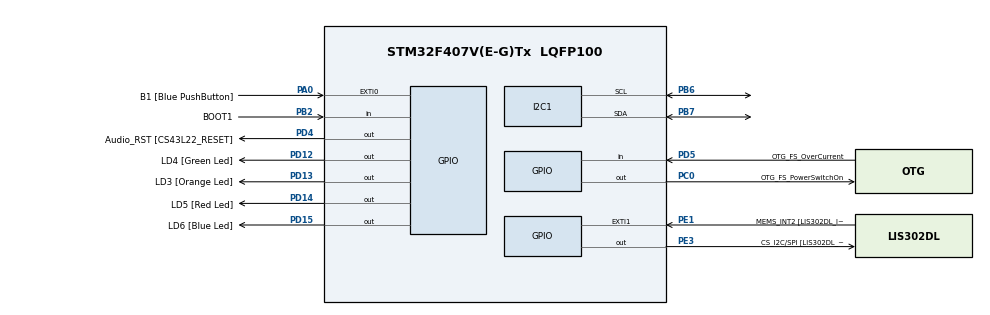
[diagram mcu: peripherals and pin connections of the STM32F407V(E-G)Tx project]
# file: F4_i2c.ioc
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Mcu.Family=STM32F4
Mcu.Name=STM32F407V(E-G)Tx
Mcu.Package=LQFP100
NVIC.PriorityGroup=NVIC_PRIORITYGROUP_0
PA0-WKUP.GPIO_Label=B1 [Blue PushButton]
PA0-WKUP.GPIO_ModeDefaultEXTI=GPIO_MODE_EVT_RISING
PA0-WKUP.GPIO_PuPd=GPIO_NOPULL
PA0-WKUP.Signal=GPXTI0
PA10.GPIO_Label=OTG_FS_ID
PA10.GPIO_Mode=GPIO_MODE_AF_PP
PA10.GPIO_PuPd=GPIO_NOPULL
PA10.GPIO_Speed=GPIO_SPEED_LOW
PA10.Signal=USB_OTG_FS_ID
PA11.GPIO_Label=OTG_FS_DM
PA11.GPIO_Mode=GPIO_MODE_AF_PP
PA11.GPIO_PuPd=GPIO_NOPULL
PA11.GPIO_Speed=GPIO_SPEED_LOW
PA11.Signal=USB_OTG_FS_DM
PA12.GPIO_Label=OTG_FS_DP
PA12.GPIO_Mode=GPIO_MODE_AF_PP
PA12.GPIO_PuPd=GPIO_NOPULL
PA12.GPIO_Speed=GPIO_SPEED_LOW
PA12.Signal=USB_OTG_FS_DP
PA13.GPIO_Label=SWDIO
PA13.Mode=Trace-Asynchronous_SW
PA13.Signal=SYS_JTMS-SWDIO
PA14.GPIO_Label=SWCLK
PA14.Mode=Trace-Asynchronous_SW
PA14.Signal=SYS_JTCK-SWCLK
PA4.GPIO_Label=I2S3_WS [CS43L22_LRCK]
PA4.GPIO_Mode=GPIO_MODE_AF_PP
PA4.GPIO_PuPd=GPIO_NOPULL
PA4.GPIO_Speed=GPIO_SPEED_LOW
PA4.Signal=I2S3_WS
PA5.GPIO_Label=SPI1_SCK [LIS302DL_SCL/SPC]
PA5.GPIO_Mode=GPIO_MODE_AF_PP
PA5.GPIO_PuPd=GPIO_NOPULL
PA5.GPIO_Speed=GPIO_SPEED_LOW
PA5.Signal=SPI1_SCK
PA6.GPIO_Label=SPI1_MISO [LIS302DL_SDO]
PA6.GPIO_Mode=GPIO_MODE_AF_PP
PA6.GPIO_PuPd=GPIO_NOPULL
PA6.GPIO_Speed=GPIO_SPEED_LOW
PA6.Signal=SPI1_MISO
PA7.GPIO_Label=SPI1_MOSI [LIS302DL_SDA/SDI/SDO]
PA7.GPIO_Mode=GPIO_MODE_AF_PP
PA7.GPIO_PuPd=GPIO_NOPULL
PA7.GPIO_Speed=GPIO_SPEED_LOW
PA7.Signal=SPI1_MOSI
PA9.GPIO_Label=VBUS_FS
PA9.GPIO_Mode=GPIO_MODE_INPUT
PA9.GPIO_PuPd=GPIO_NOPULL
PA9.Signal=USB_OTG_FS_VBUS
PB10.GPIO_Label=CLK_IN [MP45DT02_CLK]
PB10.GPIO_Mode=GPIO_MODE_AF_PP
PB10.GPIO_PuPd=GPIO_NOPULL
PB10.GPIO_Speed=GPIO_SPEED_LOW
PB10.Signal=I2S2_CK
PB2.GPIO_Label=BOOT1
PB2.GPIO_Mode=GPIO_MODE_INPUT
PB2.GPIO_PuPd=GPIO_NOPULL
PB2.Signal=GPIO_Input
PB3.GPIO_Label=SWO
PB3.Mode=Trace-Asynchronous_SW
PB3.Signal=SYS_JTDO-SWO
PB6.GPIO_Mode=GPIO_MODE_AF_OD
PB6.GPIO_PuPd=GPIO_PULLUP
PB6.GPIO_Speed=GPIO_SPEED_LOW
PB6.Mode=I2C
PB6.Signal=I2C1_SCL
PB7.GPIO_Mode=GPIO_MODE_AF_OD
PB7.GPIO_PuPd=GPIO_PULLUP
PB7.GPIO_Speed=GPIO_SPEED_LOW
PB7.Mode=I2C
PB7.Signal=I2C1_SDA
PC0.GPIO_Label=OTG_FS_PowerSwitchOn
PC0.GPIO_ModeDefaultOutputPP=GPIO_MODE_OUTPUT_PP
PC0.GPIO_PuPd=GPIO_NOPULL
PC0.GPIO_Speed=GPIO_SPEED_LOW
PC0.Signal=GPIO_Output
PC10.GPIO_Label=I2S3_SCK [CS43L22_SCLK]
PC10.GPIO_Mode=GPIO_MODE_AF_PP
PC10.GPIO_PuPd=GPIO_NOPULL
PC10.GPIO_Speed=GPIO_SPEED_LOW
PC10.Signal=I2S3_CK
PC12.GPIO_Label=I2S3_SD [CS43L22_SDIN]
PC12.GPIO_Mode=GPIO_MODE_AF_PP
PC12.GPIO_PuPd=GPIO_NOPULL
PC12.GPIO_Speed=GPIO_SPEED_LOW
PC12.Signal=I2S3_SD
PC14-OSC32_IN.GPIO_Label=PC14-OSC32_IN
PC14-OSC32_IN.Signal=RCC_OSC32_IN
PC15-OSC32_OUT.GPIO_Label=PC15-OSC32_OUT
PC15-OSC32_OUT.Signal=RCC_OSC32_OUT
PC3.GPIO_Label=PDM_OUT [MP45DT02_DOUT]
PC3.GPIO_Mode=GPIO_MODE_AF_PP
PC3.GPIO_PuPd=GPIO_NOPULL
PC3.GPIO_Speed=GPIO_SPEED_LOW
PC3.Signal=I2S2_SD
PC7.GPIO_Label=I2S3_MCK [CS43L22_MCLK]
PC7.GPIO_Mode=GPIO_MODE_AF_PP
PC7.GPIO_PuPd=GPIO_NOPULL
PC7.GPIO_Speed=GPIO_SPEED_LOW
PC7.Signal=I2S3_MCK
PD12.GPIO_Label=LD4 [Green Led]
PD12.GPIO_ModeDefaultOutputPP=GPIO_MODE_OUTPUT_PP
PD12.GPIO_PuPd=GPIO_NOPULL
PD12.GPIO_Speed=GPIO_SPEED_LOW
PD12.Signal=GPIO_Output
PD13.GPIO_Label=LD3 [Orange Led]
PD13.GPIO_ModeDefaultOutputPP=GPIO_MODE_OUTPUT_PP
PD13.GPIO_PuPd=GPIO_NOPULL
PD13.GPIO_Speed=GPIO_SPEED_LOW
PD13.Signal=GPIO_Output
PD14.GPIO_Label=LD5 [Red Led]
PD14.GPIO_ModeDefaultOutputPP=GPIO_MODE_OUTPUT_PP
PD14.GPIO_PuPd=GPIO_NOPULL
PD14.GPIO_Speed=GPIO_SPEED_LOW
PD14.Signal=GPIO_Output
PD15.GPIO_Label=LD6 [Blue Led]
PD15.GPIO_ModeDefaultOutputPP=GPIO_MODE_OUTPUT_PP
PD15.GPIO_PuPd=GPIO_NOPULL
PD15.GPIO_Speed=GPIO_SPEED_LOW
PD15.Signal=GPIO_Output
PD4.GPIO_Label=Audio_RST [CS43L22_RESET]
PD4.GPIO_ModeDefaultOutputPP=GPIO_MODE_OUTPUT_PP
PD4.GPIO_PuPd=GPIO_NOPULL
PD4.GPIO_Speed=GPIO_SPEED_LOW
PD4.Signal=GPIO_Output
PD5.GPIO_Label=OTG_FS_OverCurrent
PD5.GPIO_Mode=GPIO_MODE_INPUT
PD5.GPIO_PuPd=GPIO_NOPULL
PD5.Signal=GPIO_Input
PE1.GPIO_Label=MEMS_INT2 [LIS302DL_INT2]
PE1.GPIO_ModeDefaultEXTI=GPIO_MODE_EVT_RISING
PE1.GPIO_PuPd=GPIO_NOPULL
PE1.Signal=GPXTI1
PE3.GPIO_Label=CS_I2C/SPI [LIS302DL_CS_I2C/SPI]
PE3.GPIO_ModeDefaultOutputPP=GPIO_MODE_OUTPUT_PP
PE3.GPIO_PuPd=GPIO_NOPULL
PE3.GPIO_Speed=GPIO_SPEED_LOW
PE3.Signal=GPIO_Output
PH0-OSC_IN.GPIO_Label=PH0-OSC_IN
PH0-OSC_IN.Mode=HSE-External-Oscillator
PH0-OSC_IN.Signal=RCC_OSC_IN
PH1-OSC_OUT.GPIO_Label=PH1-OSC_OUT
PH1-OSC_OUT.Mode=HSE-External-Oscillator
PH1-OSC_OUT.Signal=RCC_OSC_OUT
ProjectManager.TargetToolchain=TrueSTUDIO 4.3.1
RCC.APB1CLKDivider=RCC_HCLK_DIV4
RCC.APB2CLKDivider=RCC_HCLK_DIV2
RCC.HSE_VALUE=8000000
RCC.HSI_VALUE=16000000
RCC.LSE_VALUE=32768
RCC.PLLM=8
RCC.PLLN=336
RCC.PLLP=RCC_PLLP_DIV4
RCC.PLLQ=7
RCC.PLLSource=RCC_PLLSOURCE_HSE
RCC.SYSCLKSource=RCC_SYSCLKSOURCE_PLLCLK
VP_FREERTOS_VS_ENABLE.Mode=Enabled

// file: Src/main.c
/**
  ******************************************************************************
  * File Name          : main.c
  * Date               : 25/07/2014 10:54:28
  * Description        : Main program body
  ******************************************************************************
  *
  * COPYRIGHT(c) 2014 STMicroelectronics
  *
  * Redistribution and use in source and binary forms, with or without modification,
  * are permitted provided that the following conditions are met:
  *   1. Redistributions of source code must retain the above copyright notice,
  *      this list of conditions and the following disclaimer.
  *   2. Redistributions in binary form must reproduce the above copyright notice,
  *      this list of conditions and the following disclaimer in the documentation
  *      and/or other materials provided with the distribution.
  *   3. Neither the name of STMicroelectronics nor the names of its contributors
  *      may be used to endorse or promote products derived from this software
  *      without specific prior written permission.
  *
  * THIS SOFTWARE IS PROVIDED BY THE COPYRIGHT HOLDERS AND CONTRIBUTORS "AS IS"
  * AND ANY EXPRESS OR IMPLIED WARRANTIES, INCLUDING, BUT NOT LIMITED TO, THE
  * IMPLIED WARRANTIES OF MERCHANTABILITY AND FITNESS FOR A PARTICULAR PURPOSE ARE
  * DISCLAIMED. IN NO EVENT SHALL THE COPYRIGHT HOLDER OR CONTRIBUTORS BE LIABLE
  * FOR ANY DIRECT, INDIRECT, INCIDENTAL, SPECIAL, EXEMPLARY, OR CONSEQUENTIAL
  * DAMAGES (INCLUDING, BUT NOT LIMITED TO, PROCUREMENT OF SUBSTITUTE GOODS OR
  * SERVICES; LOSS OF USE, DATA, OR PROFITS; OR BUSINESS INTERRUPTION) HOWEVER
  * CAUSED AND ON ANY THEORY OF LIABILITY, WHETHER IN CONTRACT, STRICT LIABILITY,
  * OR TORT (INCLUDING NEGLIGENCE OR OTHERWISE) ARISING IN ANY WAY OUT OF THE USE
  * OF THIS SOFTWARE, EVEN IF ADVISED OF THE POSSIBILITY OF SUCH DAMAGE.
  *
  ******************************************************************************
  */

#include "stm32f4xx_hal.h"
#include "cmsis_os.h"

I2C_HandleTypeDef hi2c1;

/* USER CODE BEGIN 0 */
static void StartThread(void const * argument);
static void CounterThread(void const * argumnet); /* For our led counter */
/* USER CODE END 0 */

void SystemClock_Config(void);
static void StartThread(void const * argument);
static void MX_GPIO_Init(void);
static void MX_I2C1_Init(void);

int main(void)
{

  /* MCU Configuration----------------------------------------------------------*/

  /* Reset of all peripherals, Initializes the Flash interface and the Systick. */
  HAL_Init();

  /* Configure the system clock */
  SystemClock_Config();

  /* System interrupt init*/
  /* Sets the priority grouping field */
  HAL_NVIC_SetPriorityGrouping(NVIC_PRIORITYGROUP_4);
  HAL_NVIC_SetPriority(SysTick_IRQn, 0, 0);

  /* Initialize all configured peripherals */
  MX_GPIO_Init();
  MX_I2C1_Init();

  /* Code generated for FreeRTOS */
  /* Create Start thread */

  osThreadDef(USER_Thread, StartThread, osPriorityNormal, 0, 2 * configMINIMAL_STACK_SIZE);
  osThreadCreate (osThread(USER_Thread), NULL);

  /* Create Count led thread */
  osThreadDef(USER_Thread1, CounterThread, osPriorityNormal, 0, 2 * configMINIMAL_STACK_SIZE);
  osThreadCreate (osThread(USER_Thread1), NULL);

  /* Start scheduler */
  osKernelStart(NULL, NULL);

  /* We should never get here as control is now taken by the scheduler */

  while (1)
  {
  }

}

/** System Clock Configuration
*/
void SystemClock_Config(void)
{

  RCC_ClkInitTypeDef RCC_ClkInitStruct;
  RCC_OscInitTypeDef RCC_OscInitStruct;

  __PWR_CLK_ENABLE();

  __HAL_PWR_VOLTAGESCALING_CONFIG(PWR_REGULATOR_VOLTAGE_SCALE2);

  RCC_OscInitStruct.OscillatorType = RCC_OSCILLATORTYPE_HSE;
  RCC_OscInitStruct.HSEState = RCC_HSE_ON;
  RCC_OscInitStruct.PLL.PLLState = RCC_PLL_ON;
  RCC_OscInitStruct.PLL.PLLSource = RCC_PLLSOURCE_HSE;
  RCC_OscInitStruct.PLL.PLLM = 8;
  RCC_OscInitStruct.PLL.PLLN = 336;
  RCC_OscInitStruct.PLL.PLLP = RCC_PLLP_DIV4;
  RCC_OscInitStruct.PLL.PLLQ = 7;
  HAL_RCC_OscConfig(&RCC_OscInitStruct);

  RCC_ClkInitStruct.ClockType = RCC_CLOCKTYPE_SYSCLK|RCC_CLOCKTYPE_PCLK1
                              |RCC_CLOCKTYPE_PCLK2;
  RCC_ClkInitStruct.SYSCLKSource = RCC_SYSCLKSOURCE_PLLCLK;
  RCC_ClkInitStruct.AHBCLKDivider = RCC_SYSCLK_DIV1;
  RCC_ClkInitStruct.APB1CLKDivider = RCC_HCLK_DIV4;
  RCC_ClkInitStruct.APB2CLKDivider = RCC_HCLK_DIV2;
  HAL_RCC_ClockConfig(&RCC_ClkInitStruct, FLASH_LATENCY_2);

}

/* I2C1 init function */
void MX_I2C1_Init(void)
{

  hi2c1.Instance = I2C1;
  hi2c1.Init.ClockSpeed = 100000;
  hi2c1.Init.DutyCycle = I2C_DUTYCYCLE_2;
  hi2c1.Init.OwnAddress1 = 0;
  hi2c1.Init.AddressingMode = I2C_ADDRESSINGMODE_7BIT;
  hi2c1.Init.DualAddressMode = I2C_DUALADDRESS_DISABLED;
  hi2c1.Init.OwnAddress2 = 0;
  hi2c1.Init.GeneralCallMode = I2C_GENERALCALL_DISABLED;
  hi2c1.Init.NoStretchMode = I2C_NOSTRETCH_DISABLED;
  HAL_I2C_Init(&hi2c1);

}

/** Configure pins as
        * Analog
        * Input
        * Output
        * EVENT_OUT
        * EXTI
     PC3   ------> I2S2_SD
     PA4   ------> I2S3_WS
     PA5   ------> SPI1_SCK
     PA6   ------> SPI1_MISO
     PA7   ------> SPI1_MOSI
     PB10   ------> I2S2_CK
     PC7   ------> I2S3_MCK
     PA9   ------> USB_OTG_FS_VBUS
     PA10   ------> USB_OTG_FS_ID
     PA11   ------> USB_OTG_FS_DM
     PA12   ------> USB_OTG_FS_DP
     PC10   ------> I2S3_CK
     PC12   ------> I2S3_SD
*/
void MX_GPIO_Init(void)
{

  GPIO_InitTypeDef GPIO_InitStruct;

  /* GPIO Ports Clock Enable */
  __GPIOE_CLK_ENABLE();
  __GPIOC_CLK_ENABLE();
  __GPIOH_CLK_ENABLE();
  __GPIOA_CLK_ENABLE();
  __GPIOB_CLK_ENABLE();
  __GPIOD_CLK_ENABLE();

  /*Configure GPIO pin : PE3 */
  GPIO_InitStruct.Pin = GPIO_PIN_3;
  GPIO_InitStruct.Mode = GPIO_MODE_OUTPUT_PP;
  GPIO_InitStruct.Pull = GPIO_NOPULL;
  GPIO_InitStruct.Speed = GPIO_SPEED_LOW;
  HAL_GPIO_Init(GPIOE, &GPIO_InitStruct);

  /*Configure GPIO pin : PC0 */
  GPIO_InitStruct.Pin = GPIO_PIN_0;
  GPIO_InitStruct.Mode = GPIO_MODE_OUTPUT_PP;
  GPIO_InitStruct.Pull = GPIO_NOPULL;
  GPIO_InitStruct.Speed = GPIO_SPEED_LOW;
  HAL_GPIO_Init(GPIOC, &GPIO_InitStruct);

  /*Configure GPIO pin : PC3 */
  GPIO_InitStruct.Pin = GPIO_PIN_3;
  GPIO_InitStruct.Mode = GPIO_MODE_AF_PP;
  GPIO_InitStruct.Pull = GPIO_NOPULL;
  GPIO_InitStruct.Speed = GPIO_SPEED_LOW;
  GPIO_InitStruct.Alternate = GPIO_AF5_SPI2;
  HAL_GPIO_Init(GPIOC, &GPIO_InitStruct);

  /*Configure GPIO pin : PA0 */
  GPIO_InitStruct.Pin = GPIO_PIN_0;
  GPIO_InitStruct.Mode = GPIO_MODE_EVT_RISING;
  GPIO_InitStruct.Pull = GPIO_NOPULL;
  HAL_GPIO_Init(GPIOA, &GPIO_InitStruct);

  /*Configure GPIO pin : PA4 */
  GPIO_InitStruct.Pin = GPIO_PIN_4;
  GPIO_InitStruct.Mode = GPIO_MODE_AF_PP;
  GPIO_InitStruct.Pull = GPIO_NOPULL;
  GPIO_InitStruct.Speed = GPIO_SPEED_LOW;
  GPIO_InitStruct.Alternate = GPIO_AF6_SPI3;
  HAL_GPIO_Init(GPIOA, &GPIO_InitStruct);

  /*Configure GPIO pins : PA5 PA6 PA7 */
  GPIO_InitStruct.Pin = GPIO_PIN_5|GPIO_PIN_6|GPIO_PIN_7;
  GPIO_InitStruct.Mode = GPIO_MODE_AF_PP;
  GPIO_InitStruct.Pull = GPIO_NOPULL;
  GPIO_InitStruct.Speed = GPIO_SPEED_LOW;
  GPIO_InitStruct.Alternate = GPIO_AF5_SPI1;
  HAL_GPIO_Init(GPIOA, &GPIO_InitStruct);

  /*Configure GPIO pin : PB2 */
  GPIO_InitStruct.Pin = GPIO_PIN_2;
  GPIO_InitStruct.Mode = GPIO_MODE_INPUT;
  GPIO_InitStruct.Pull = GPIO_NOPULL;
  HAL_GPIO_Init(GPIOB, &GPIO_InitStruct);

  /*Configure GPIO pin : PB10 */
  GPIO_InitStruct.Pin = GPIO_PIN_10;
  GPIO_InitStruct.Mode = GPIO_MODE_AF_PP;
  GPIO_InitStruct.Pull = GPIO_NOPULL;
  GPIO_InitStruct.Speed = GPIO_SPEED_LOW;
  GPIO_InitStruct.Alternate = GPIO_AF5_SPI2;
  HAL_GPIO_Init(GPIOB, &GPIO_InitStruct);

  /*Configure GPIO pins : PD12 PD13 PD14 PD15
                           PD4 */
  GPIO_InitStruct.Pin = GPIO_PIN_12|GPIO_PIN_13|GPIO_PIN_14|GPIO_PIN_15
                          |GPIO_PIN_4;
  GPIO_InitStruct.Mode = GPIO_MODE_OUTPUT_PP;
  GPIO_InitStruct.Pull = GPIO_NOPULL;
  GPIO_InitStruct.Speed = GPIO_SPEED_LOW;
  HAL_GPIO_Init(GPIOD, &GPIO_InitStruct);

  /*Configure GPIO pins : PC7 PC10 PC12 */
  GPIO_InitStruct.Pin = GPIO_PIN_7|GPIO_PIN_10|GPIO_PIN_12;
  GPIO_InitStruct.Mode = GPIO_MODE_AF_PP;
  GPIO_InitStruct.Pull = GPIO_NOPULL;
  GPIO_InitStruct.Speed = GPIO_SPEED_LOW;
  GPIO_InitStruct.Alternate = GPIO_AF6_SPI3;
  HAL_GPIO_Init(GPIOC, &GPIO_InitStruct);

  /*Configure GPIO pin : PA9 */
  GPIO_InitStruct.Pin = GPIO_PIN_9;
  GPIO_InitStruct.Mode = GPIO_MODE_INPUT;
  GPIO_InitStruct.Pull = GPIO_NOPULL;
  HAL_GPIO_Init(GPIOA, &GPIO_InitStruct);

  /*Configure GPIO pins : PA10 PA11 PA12 */
  GPIO_InitStruct.Pin = GPIO_PIN_10|GPIO_PIN_11|GPIO_PIN_12;
  GPIO_InitStruct.Mode = GPIO_MODE_AF_PP;
  GPIO_InitStruct.Pull = GPIO_NOPULL;
  GPIO_InitStruct.Speed = GPIO_SPEED_LOW;
  GPIO_InitStruct.Alternate = GPIO_AF10_OTG_FS;
  HAL_GPIO_Init(GPIOA, &GPIO_InitStruct);

  /*Configure GPIO pin : PD5 */
  GPIO_InitStruct.Pin = GPIO_PIN_5;
  GPIO_InitStruct.Mode = GPIO_MODE_INPUT;
  GPIO_InitStruct.Pull = GPIO_NOPULL;
  HAL_GPIO_Init(GPIOD, &GPIO_InitStruct);

  /*Configure GPIO pin : PE1 */
  GPIO_InitStruct.Pin = GPIO_PIN_1;
  GPIO_InitStruct.Mode = GPIO_MODE_EVT_RISING;
  GPIO_InitStruct.Pull = GPIO_NOPULL;
  HAL_GPIO_Init(GPIOE, &GPIO_InitStruct);

}

static void StartThread(void const * argument) {

  /* USER CODE BEGIN 5 */

  /* Infinite loop */
  for(;;)
  {
    osDelay(1);
  }
}

static void CounterThread(void const * argument) {
    uint8_t count = 0;
    char data[2];

    /* We need to send data to the direction
     * register first to setup our led counter as output
     */
    data[0] = 0x00;
    data[1] = 0x00;
    HAL_I2C_Master_Transmit(&hi2c1, (uint16_t) (0x21 << 1), (uint8_t *) data, 2, 1000);

    /* Infinite loop */
    data[0] = 0x14;
    for(;;)
    {
      data[1] = count;
      HAL_I2C_Master_Transmit(&hi2c1, (uint16_t) (0x21 << 1), (uint8_t*) data, 2, 1000);
      count ++;
      osDelay(100);
    }
  }

  /* USER CODE END 5 */

/************************ (C) COPYRIGHT STMicroelectronics *****END OF FILE****/
